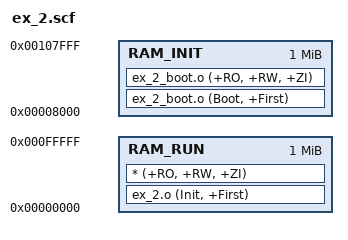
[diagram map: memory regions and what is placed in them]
RAM_LOAD 0x00008000 0x100000
{
    RAM_INIT 0x00008000 0x100000
    {
    	ex_2_boot.o	(Boot, +First)
    	ex_2_boot.o	(+RO, +RW, +ZI)
    }
    
    RAM_RUN 0x00000000 0x100000
    {
        ex_2.o	(Init, +First)
        *	(+RO, +RW, +ZI)
    }
}
